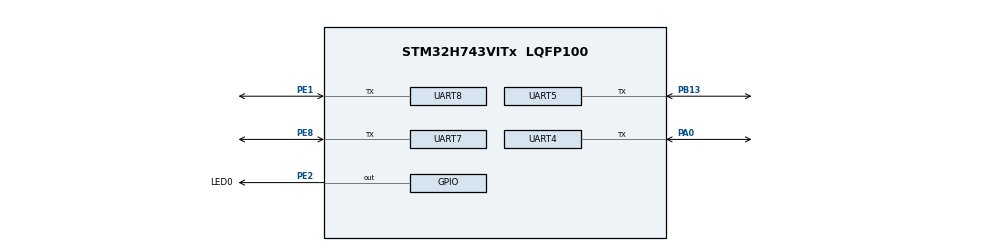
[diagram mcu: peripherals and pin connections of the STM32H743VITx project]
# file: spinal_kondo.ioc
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Mcu.Family=STM32H7
RCC.CortexFreq_Value=64000000
PE1.Mode=Half_duplex(single_wire_mode)
PB13.Signal=UART5_TX
ProjectManager.StackSize=0x400
PE8.Mode=Half_duplex(single_wire_mode)
ProjectManager.TargetToolchain=STM32CubeIDE
UART4.BaudRate=1250000
RCC.HCLKFreq_Value=64000000
RCC.USBFreq_Value=129000000
PE1.Signal=UART8_TX
board=custom
RCC.APB2Freq_Value=64000000
PE8.Signal=UART7_TX
RCC.ADCFreq_Value=129000000
PA0.Mode=Half_duplex(single_wire_mode)
PE2.Signal=GPIO_Output
Mcu.Name=STM32H743VITx
PA0.Signal=UART4_TX
RCC.APB3Freq_Value=64000000
RCC.SYSCLKFreq_VALUE=64000000
Mcu.Package=LQFP100
UART8.BaudRate=1250000
ProjectManager.HeapSize=0x200
UART7.BaudRate=1250000
NVIC.PriorityGroup=NVIC_PRIORITYGROUP_4
RCC.APB4Freq_Value=64000000
UART5.BaudRate=1250000
PB13.Mode=Half_duplex(single_wire_mode)
RCC.APB1Freq_Value=64000000
PE2.GPIO_Label=LED0

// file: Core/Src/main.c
/* USER CODE BEGIN Header */
/**
  ******************************************************************************
  * @file           : main.c
  * @brief          : Main program body
  ******************************************************************************
  * @attention
  *
  * <h2><center>&copy; Copyright (c) 2023 STMicroelectronics.
  * All rights reserved.</center></h2>
  *
  * This software component is licensed by ST under BSD 3-Clause license,
  * the "License"; You may not use this file except in compliance with the
  * License. You may obtain a copy of the License at:
  *                        opensource.org/licenses/BSD-3-Clause
  *
  ******************************************************************************
  */
/* USER CODE END Header */
#include "main.h"

/* USER CODE BEGIN Includes */
#include "kondo.h"
/* USER CODE END Includes */

UART_HandleTypeDef huart4;
UART_HandleTypeDef huart5;
UART_HandleTypeDef huart7;
UART_HandleTypeDef huart8;

void SystemClock_Config(void);
static void MX_GPIO_Init(void);
static void MX_UART4_Init(void);
static void MX_UART5_Init(void);
static void MX_UART7_Init(void);
static void MX_UART8_Init(void);

int main(void)
{

  /* MCU Configuration--------------------------------------------------------*/

  /* Reset of all peripherals, Initializes the Flash interface and the Systick. */
  HAL_Init();

  /* Configure the system clock */
  SystemClock_Config();

  /* Initialize all configured peripherals */
  MX_GPIO_Init();
  MX_UART4_Init();
  MX_UART5_Init();
  MX_UART7_Init();
  MX_UART8_Init();
  /* USER CODE BEGIN 2 */
  kondo_servo_t kondo_servo = {1, 1250000, 0, huart8, 0, 0, 0, 0};

  /* USER CODE END 2 */

  /* Infinite loop */
  /* USER CODE BEGIN WHILE */
  while (1)
  {
	  HAL_Delay(1000);
	  HAL_GPIO_TogglePin(LED0_GPIO_Port, LED0_Pin);
	  setPosition(&kondo_servo, 9000);

	  HAL_Delay(1000);
	  HAL_GPIO_TogglePin(LED0_GPIO_Port, LED0_Pin);
	  setPosition(&kondo_servo, 9000);

	  HAL_Delay(1000);
	  HAL_GPIO_TogglePin(LED0_GPIO_Port, LED0_Pin);
	  setPosition(&kondo_servo, 7500);

	  HAL_Delay(1000);
	  HAL_GPIO_TogglePin(LED0_GPIO_Port, LED0_Pin);
	  setPosition(&kondo_servo, 6000);

    /* USER CODE END WHILE */

  }
}

void SystemClock_Config(void)
{
  RCC_OscInitTypeDef RCC_OscInitStruct = {0};
  RCC_ClkInitTypeDef RCC_ClkInitStruct = {0};

  /** Supply configuration update enable
  */
  HAL_PWREx_ConfigSupply(PWR_LDO_SUPPLY);
  /** Configure the main internal regulator output voltage
  */
  __HAL_PWR_VOLTAGESCALING_CONFIG(PWR_REGULATOR_VOLTAGE_SCALE3);

  while(!__HAL_PWR_GET_FLAG(PWR_FLAG_VOSRDY)) {}
  /** Initializes the RCC Oscillators according to the specified parameters
  * in the RCC_OscInitTypeDef structure.
  */
  RCC_OscInitStruct.OscillatorType = RCC_OSCILLATORTYPE_HSI;
  RCC_OscInitStruct.HSIState = RCC_HSI_DIV1;
  RCC_OscInitStruct.HSICalibrationValue = RCC_HSICALIBRATION_DEFAULT;
  RCC_OscInitStruct.PLL.PLLState = RCC_PLL_NONE;
  if (HAL_RCC_OscConfig(&RCC_OscInitStruct) != HAL_OK)
  {
    Error_Handler();
  }
  /** Initializes the CPU, AHB and APB buses clocks
  */
  RCC_ClkInitStruct.ClockType = RCC_CLOCKTYPE_HCLK|RCC_CLOCKTYPE_SYSCLK
                              |RCC_CLOCKTYPE_PCLK1|RCC_CLOCKTYPE_PCLK2
                              |RCC_CLOCKTYPE_D3PCLK1|RCC_CLOCKTYPE_D1PCLK1;
  RCC_ClkInitStruct.SYSCLKSource = RCC_SYSCLKSOURCE_HSI;
  RCC_ClkInitStruct.SYSCLKDivider = RCC_SYSCLK_DIV1;
  RCC_ClkInitStruct.AHBCLKDivider = RCC_HCLK_DIV1;
  RCC_ClkInitStruct.APB3CLKDivider = RCC_APB3_DIV1;
  RCC_ClkInitStruct.APB1CLKDivider = RCC_APB1_DIV1;
  RCC_ClkInitStruct.APB2CLKDivider = RCC_APB2_DIV1;
  RCC_ClkInitStruct.APB4CLKDivider = RCC_APB4_DIV1;

  if (HAL_RCC_ClockConfig(&RCC_ClkInitStruct, FLASH_LATENCY_1) != HAL_OK)
  {
    Error_Handler();
  }
}

static void MX_UART4_Init(void)
{

  huart4.Instance = UART4;
  huart4.Init.BaudRate = 1250000;
  huart4.Init.WordLength = UART_WORDLENGTH_8B;
  huart4.Init.StopBits = UART_STOPBITS_1;
  huart4.Init.Parity = UART_PARITY_NONE;
  huart4.Init.Mode = UART_MODE_TX_RX;
  huart4.Init.HwFlowCtl = UART_HWCONTROL_NONE;
  huart4.Init.OverSampling = UART_OVERSAMPLING_16;
  huart4.Init.OneBitSampling = UART_ONE_BIT_SAMPLE_DISABLE;
  huart4.Init.ClockPrescaler = UART_PRESCALER_DIV1;
  huart4.AdvancedInit.AdvFeatureInit = UART_ADVFEATURE_NO_INIT;
  if (HAL_HalfDuplex_Init(&huart4) != HAL_OK)
  {
    Error_Handler();
  }
  if (HAL_UARTEx_SetTxFifoThreshold(&huart4, UART_TXFIFO_THRESHOLD_1_8) != HAL_OK)
  {
    Error_Handler();
  }
  if (HAL_UARTEx_SetRxFifoThreshold(&huart4, UART_RXFIFO_THRESHOLD_1_8) != HAL_OK)
  {
    Error_Handler();
  }
  if (HAL_UARTEx_DisableFifoMode(&huart4) != HAL_OK)
  {
    Error_Handler();
  }

}

static void MX_UART5_Init(void)
{

  huart5.Instance = UART5;
  huart5.Init.BaudRate = 1250000;
  huart5.Init.WordLength = UART_WORDLENGTH_8B;
  huart5.Init.StopBits = UART_STOPBITS_1;
  huart5.Init.Parity = UART_PARITY_NONE;
  huart5.Init.Mode = UART_MODE_TX_RX;
  huart5.Init.HwFlowCtl = UART_HWCONTROL_NONE;
  huart5.Init.OverSampling = UART_OVERSAMPLING_16;
  huart5.Init.OneBitSampling = UART_ONE_BIT_SAMPLE_DISABLE;
  huart5.Init.ClockPrescaler = UART_PRESCALER_DIV1;
  huart5.AdvancedInit.AdvFeatureInit = UART_ADVFEATURE_NO_INIT;
  if (HAL_HalfDuplex_Init(&huart5) != HAL_OK)
  {
    Error_Handler();
  }
  if (HAL_UARTEx_SetTxFifoThreshold(&huart5, UART_TXFIFO_THRESHOLD_1_8) != HAL_OK)
  {
    Error_Handler();
  }
  if (HAL_UARTEx_SetRxFifoThreshold(&huart5, UART_RXFIFO_THRESHOLD_1_8) != HAL_OK)
  {
    Error_Handler();
  }
  if (HAL_UARTEx_DisableFifoMode(&huart5) != HAL_OK)
  {
    Error_Handler();
  }

}

static void MX_UART7_Init(void)
{

  huart7.Instance = UART7;
  huart7.Init.BaudRate = 1250000;
  huart7.Init.WordLength = UART_WORDLENGTH_8B;
  huart7.Init.StopBits = UART_STOPBITS_1;
  huart7.Init.Parity = UART_PARITY_NONE;
  huart7.Init.Mode = UART_MODE_TX_RX;
  huart7.Init.HwFlowCtl = UART_HWCONTROL_NONE;
  huart7.Init.OverSampling = UART_OVERSAMPLING_16;
  huart7.Init.OneBitSampling = UART_ONE_BIT_SAMPLE_DISABLE;
  huart7.Init.ClockPrescaler = UART_PRESCALER_DIV1;
  huart7.AdvancedInit.AdvFeatureInit = UART_ADVFEATURE_NO_INIT;
  if (HAL_HalfDuplex_Init(&huart7) != HAL_OK)
  {
    Error_Handler();
  }
  if (HAL_UARTEx_SetTxFifoThreshold(&huart7, UART_TXFIFO_THRESHOLD_1_8) != HAL_OK)
  {
    Error_Handler();
  }
  if (HAL_UARTEx_SetRxFifoThreshold(&huart7, UART_RXFIFO_THRESHOLD_1_8) != HAL_OK)
  {
    Error_Handler();
  }
  if (HAL_UARTEx_DisableFifoMode(&huart7) != HAL_OK)
  {
    Error_Handler();
  }

}

static void MX_UART8_Init(void)
{

  huart8.Instance = UART8;
  huart8.Init.BaudRate = 1250000;
  huart8.Init.WordLength = UART_WORDLENGTH_8B;
  huart8.Init.StopBits = UART_STOPBITS_1;
  huart8.Init.Parity = UART_PARITY_NONE;
  huart8.Init.Mode = UART_MODE_TX_RX;
  huart8.Init.HwFlowCtl = UART_HWCONTROL_NONE;
  huart8.Init.OverSampling = UART_OVERSAMPLING_16;
  huart8.Init.OneBitSampling = UART_ONE_BIT_SAMPLE_DISABLE;
  huart8.Init.ClockPrescaler = UART_PRESCALER_DIV1;
  huart8.AdvancedInit.AdvFeatureInit = UART_ADVFEATURE_NO_INIT;
  if (HAL_HalfDuplex_Init(&huart8) != HAL_OK)
  {
    Error_Handler();
  }
  if (HAL_UARTEx_SetTxFifoThreshold(&huart8, UART_TXFIFO_THRESHOLD_1_8) != HAL_OK)
  {
    Error_Handler();
  }
  if (HAL_UARTEx_SetRxFifoThreshold(&huart8, UART_RXFIFO_THRESHOLD_1_8) != HAL_OK)
  {
    Error_Handler();
  }
  if (HAL_UARTEx_DisableFifoMode(&huart8) != HAL_OK)
  {
    Error_Handler();
  }

}

static void MX_GPIO_Init(void)
{
  GPIO_InitTypeDef GPIO_InitStruct = {0};

  /* GPIO Ports Clock Enable */
  __HAL_RCC_GPIOE_CLK_ENABLE();
  __HAL_RCC_GPIOA_CLK_ENABLE();
  __HAL_RCC_GPIOB_CLK_ENABLE();

  /*Configure GPIO pin Output Level */
  HAL_GPIO_WritePin(LED0_GPIO_Port, LED0_Pin, GPIO_PIN_RESET);

  /*Configure GPIO pin : LED0_Pin */
  GPIO_InitStruct.Pin = LED0_Pin;
  GPIO_InitStruct.Mode = GPIO_MODE_OUTPUT_PP;
  GPIO_InitStruct.Pull = GPIO_NOPULL;
  GPIO_InitStruct.Speed = GPIO_SPEED_FREQ_LOW;
  HAL_GPIO_Init(LED0_GPIO_Port, &GPIO_InitStruct);

}

void Error_Handler(void)
{
  __disable_irq();
  while (1)
  {
  }
}

/************************ (C) COPYRIGHT STMicroelectronics *****END OF FILE****/
